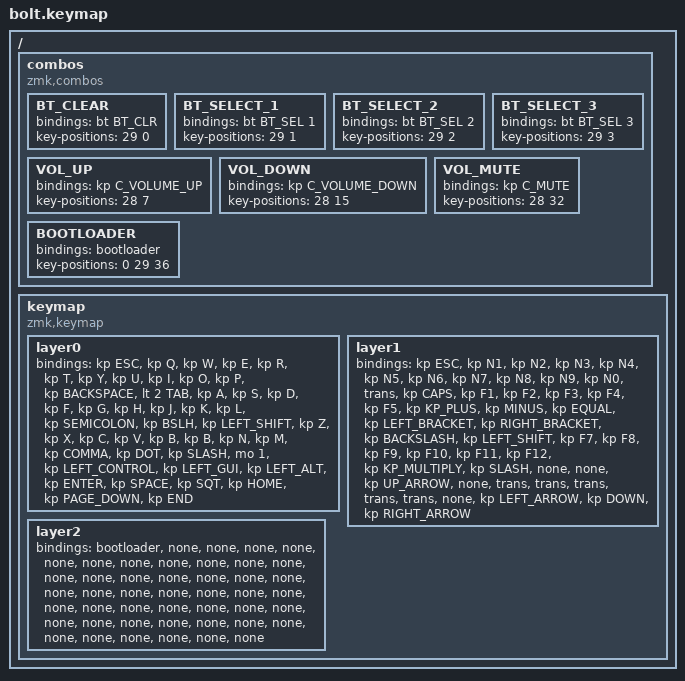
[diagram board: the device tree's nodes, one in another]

  /*
  * Copyright (c) 2020 The ZMK Contributors
  *
  * SPDX-License-Identifier: MIT
  */

  #include <behaviors.dtsi>
  #include <dt-bindings/zmk/keys.h>
  #include <dt-bindings/zmk/bt.h>
  #include <dt-bindings/zmk/ext_power.h>

  / {
    combos {
        compatible = "zmk,combos";

        BT_CLEAR {
            bindings = <&bt BT_CLR>;
            key-positions = <29 0>;  /*B + ESC*/
        };

        BT_SELECT_1 {
            bindings = <&bt BT_SEL 1>;
            key-positions = <29 1>;  /*B + Q*/
        };

        BT_SELECT_2 {
            bindings = <&bt BT_SEL 2>;
            key-positions = <29 2>;  /*B + W*/
        };

        BT_SELECT_3 {
            bindings = <&bt BT_SEL 3>;
            key-positions = <29 3>;  /*B + E*/
        };

        VOL_UP {
            bindings = <&kp C_VOLUME_UP>;
            key-positions = <28 7>;  /*V + U*/
        };

        VOL_DOWN {
            bindings = <&kp C_VOLUME_DOWN>;
            key-positions = <28 15>;  /*V + D*/
        };

        VOL_MUTE {
            bindings = <&kp C_MUTE>;
            key-positions = <28 32>;  /*V + M*/
        };

        BOOTLOADER {
            bindings = <&bootloader>;
            key-positions = <0 29 36>;  /*FN + B + ESC*/
        };
    };

    keymap {
        compatible = "zmk,keymap";

        layer0 {
            bindings = <
&kp ESC  &kp Q  &kp W  &kp E  &kp R  &kp T  &kp Y  &kp U  &kp I  &kp O  &kp P  &kp BACKSPACE  &lt 2 TAB  &kp A  &kp S  &kp D  &kp F  &kp G  &kp H  &kp J  &kp K  &kp L  &kp SEMICOLON  &kp BSLH  &kp LEFT_SHIFT  &kp Z  &kp X  &kp C  &kp V  &kp B  &kp B  &kp N  &kp M  &kp COMMA  &kp DOT  &kp SLASH  &mo 1  &kp LEFT_CONTROL  &kp LEFT_GUI  &kp LEFT_ALT  &kp ENTER  &kp SPACE  &kp SQT  &kp HOME  &kp PAGE_DOWN  &kp END
            >;
        };

        layer1 {
            bindings = <
&kp ESC  &kp N1  &kp N2  &kp N3  &kp N4  &kp N5  &kp N6  &kp N7  &kp N8  &kp N9  &kp N0  &trans  &kp CAPS  &kp F1  &kp F2  &kp F3  &kp F4  &kp F5  &kp KP_PLUS  &kp MINUS  &kp EQUAL  &kp LEFT_BRACKET  &kp RIGHT_BRACKET  &kp BACKSLASH  &kp LEFT_SHIFT  &kp F7  &kp F8  &kp F9  &kp F10  &kp F11  &kp F12  &kp KP_MULTIPLY  &kp SLASH  &none  &none  &kp UP_ARROW  &none  &trans  &trans  &trans  &trans  &trans  &none  &kp LEFT_ARROW  &kp DOWN  &kp RIGHT_ARROW
            >;
        };

        layer2 {
            bindings = <
&bootloader  &none  &none  &none  &none  &none  &none  &none  &none  &none  &none  &none  &none  &none  &none  &none  &none  &none  &none  &none  &none  &none  &none  &none  &none  &none  &none  &none  &none  &none  &none  &none  &none  &none  &none  &none  &none  &none  &none  &none  &none  &none  &none  &none  &none  &none
            >;
        };
    };
};

